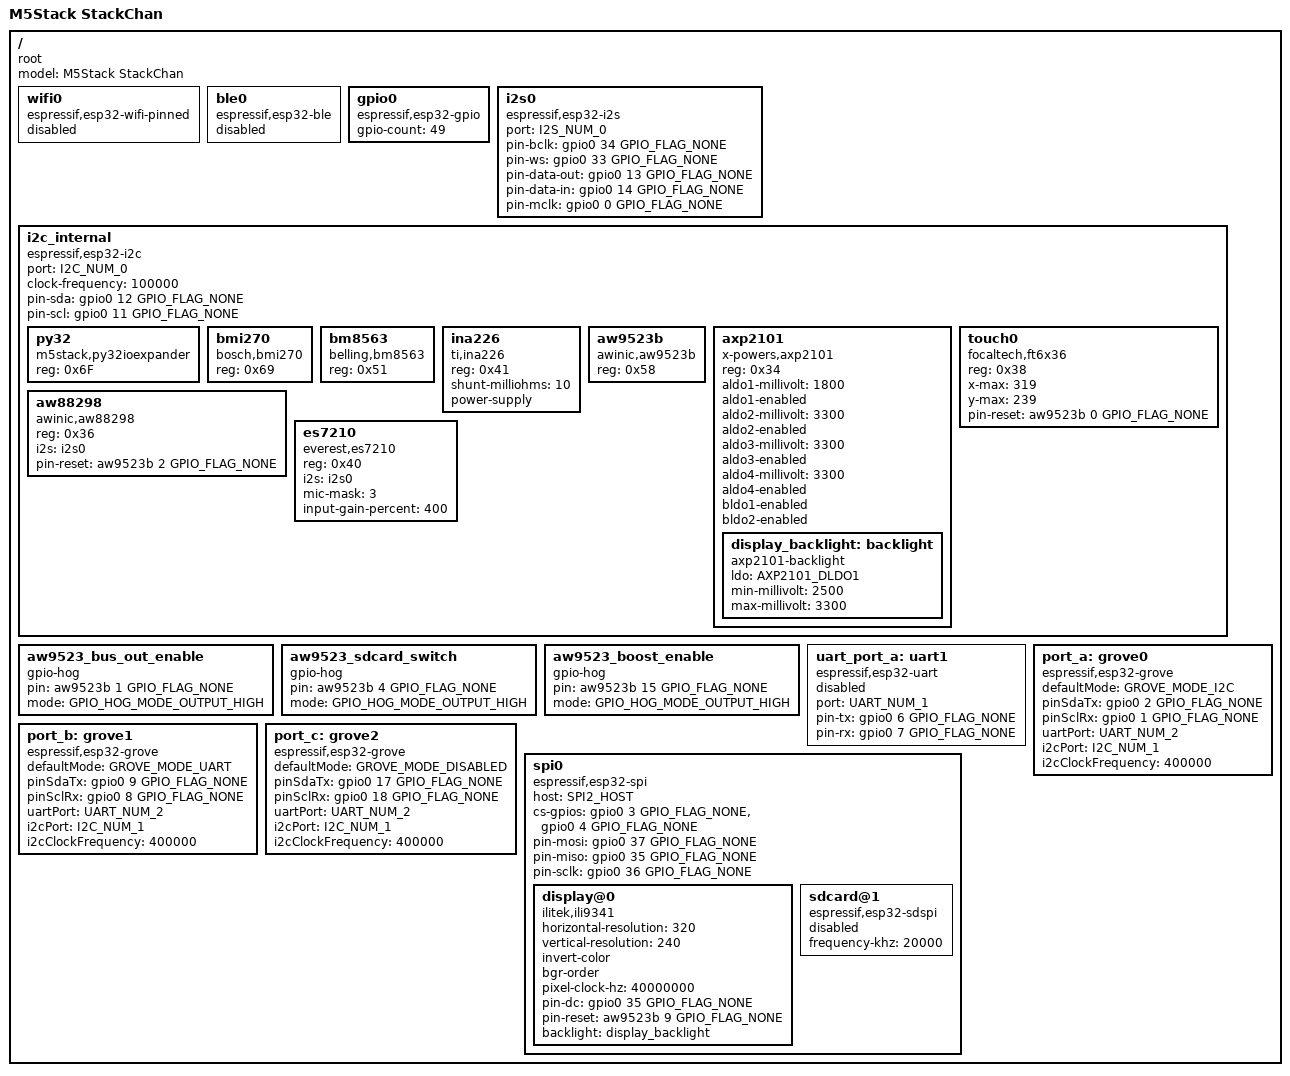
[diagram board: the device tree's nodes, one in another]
/dts-v1/;

#include <tactility/bindings/root.h>
#include <tactility/bindings/esp32_ble.h>
#include <tactility/bindings/esp32_wifi_pinned.h>
#include <tactility/bindings/esp32_gpio.h>
#include <tactility/bindings/esp32_grove.h>
#include <tactility/bindings/esp32_i2c.h>
#include <tactility/bindings/esp32_i2s.h>
#include <tactility/bindings/esp32_spi.h>
#include <tactility/bindings/esp32_uart.h>
#include <bindings/bmi270.h>
#include <bindings/bm8563.h>
#include <bindings/ina226.h>
#include <bindings/py32ioexpander.h>
#include <bindings/aw9523b.h>
#include <bindings/axp2101.h>
#include <bindings/axp2101_backlight.h>
#include <bindings/ft6x36.h>
#include <bindings/aw88298.h>
#include <bindings/es7210.h>
#include <bindings/ili9341.h>
#include <tactility/bindings/esp32_sdspi.h>
#include <tactility/bindings/gpio_hog.h>

// Reference: https://docs.m5stack.com/en/StackChan
/ {
	compatible = "root";
	model = "M5Stack StackChan";

	wifi0 {
		compatible = "espressif,esp32-wifi-pinned";
		status = "disabled";
	};

	ble0 {
		compatible = "espressif,esp32-ble";
		status = "disabled";
	};

	gpio0 {
		compatible = "espressif,esp32-gpio";
		gpio-count = <49>;
	};

	// AW88298 speaker + ES7210 microphone
	i2s0: i2s0 {
		compatible = "espressif,esp32-i2s";
		port = <I2S_NUM_0>;
		pin-bclk     = <&gpio0 34 GPIO_FLAG_NONE>;
		pin-ws       = <&gpio0 33 GPIO_FLAG_NONE>;
		pin-data-out = <&gpio0 13 GPIO_FLAG_NONE>;
		pin-data-in  = <&gpio0 14 GPIO_FLAG_NONE>;
		pin-mclk     = <&gpio0 0  GPIO_FLAG_NONE>;
	};

	i2c_internal {
		compatible = "espressif,esp32-i2c";
		port = <I2C_NUM_0>;
		clock-frequency = <100000>;
		pin-sda = <&gpio0 12 GPIO_FLAG_NONE>;
		pin-scl = <&gpio0 11 GPIO_FLAG_NONE>;

		// PY32L020 body IO expander — controls WS2812C LED ring (12 LEDs)
		py32 {
			compatible = "m5stack,py32ioexpander";
			reg = <0x6F>;
		};

		bmi270 {
			compatible = "bosch,bmi270";
			reg = <0x69>;
		};

		bm8563 {
			compatible = "belling,bm8563";
			reg = <0x51>;
		};

		ina226 {
			compatible = "ti,ina226";
			reg = <0x41>;
			shunt-milliohms = <10>;
			power-supply;
		};

		// AW9523B pin map (same wiring as CoreS3):
		// P0_0 = touch reset, P0_1 = bus-out enable, P0_2 = AW88298 reset,
		// P0_4 = SD card switch, P1_1 = LCD reset, P1_7 = boost enable (SY7088)
		aw9523b: aw9523b {
			compatible = "awinic,aw9523b";
			reg = <0x58>;
		};

		// Same rail assignment as CoreS3: ALDO1=AW88298, ALDO2=ES7210, ALDO3=camera
		// (not yet implemented, but harmless to power), ALDO4=TF/SD card. BLDO1/BLDO2 are
		// enabled with no specific voltage requirement - see the module's device_listener.
		axp2101 {
			compatible = "x-powers,axp2101";
			reg = <0x34>;
			aldo1-millivolt = <1800>;
			aldo1-enabled;
			aldo2-millivolt = <3300>;
			aldo2-enabled;
			aldo3-millivolt = <3300>;
			aldo3-enabled;
			aldo4-millivolt = <3300>;
			aldo4-enabled;
			bldo1-enabled;
			bldo2-enabled;

			// LCD backlight (DLDO1). Raw register codes [20,28] from the deprecated driver
			// map to [2500,3300]mV.
			display_backlight: backlight {
				compatible = "axp2101-backlight";
				ldo = <AXP2101_DLDO1>;
				min-millivolt = <2500>;
				max-millivolt = <3300>;
			};
		};

		touch0 {
			compatible = "focaltech,ft6x36";
			reg = <0x38>;
			x-max = <319>;
			y-max = <239>;
			pin-reset = <&aw9523b 0 GPIO_FLAG_NONE>;
		};

		aw88298 {
			compatible = "awinic,aw88298";
			reg = <0x36>;
			i2s = <&i2s0>;
			pin-reset = <&aw9523b 2 GPIO_FLAG_NONE>;
		};

		es7210 {
			compatible = "everest,es7210";
			reg = <0x40>;
			i2s = <&i2s0>;
			// Only MIC1/MIC2 are wired to real capsules (see schematic); MIC3/MIC4
			// slots carry AEC_P/AEC_N reference signal, not microphone audio.
			mic-mask = <3>;
			// M5Unified applies a 4x post-gain "magnification" for this exact mic
			// wiring (see M5Unified.cpp _mic_data_cb_cores3): the ES7210's own
			// hardware ADC gain (already near-max via the default 90% input volume
			// setting, ~34dB of its 0-37.5dB range) still isn't enough for these
			// capsules on their own.
			input-gain-percent = <400>;
		};

		// TODO: Si12T 3-zone head touch @ 0x68 — INT active-low, 10kΩ pull-up to 3.3V; driver not yet implemented
		// TODO: GC0308 camera @ 0x21 — requires i2c_master driver, not yet available
		// TODO: LTR-553ALS-WA proximity/light @ 0x23 — no driver yet
		// TODO: BMM150 magnetometer @ 0x10 — accessible only via BMI270 aux I2C
	};

	// Bus-out enable and SD card power switch are AW9523B pins with no owning peripheral
	// driver. Touch reset, AW88298 reset and LCD reset are handled directly by their own
	// device's pin-reset property instead (see touch0/aw88298/display@0 above/below).
	aw9523_bus_out_enable {
		compatible = "gpio-hog";
		pin = <&aw9523b 1 GPIO_FLAG_NONE>;
		mode = <GPIO_HOG_MODE_OUTPUT_HIGH>;
	};

	aw9523_sdcard_switch {
		compatible = "gpio-hog";
		pin = <&aw9523b 4 GPIO_FLAG_NONE>;
		mode = <GPIO_HOG_MODE_OUTPUT_HIGH>;
	};

	aw9523_boost_enable {
		compatible = "gpio-hog";
		pin = <&aw9523b 15 GPIO_FLAG_NONE>;
		mode = <GPIO_HOG_MODE_OUTPUT_HIGH>;
	};

	// TODO: Servo UART (SCS9009, 1 Mbaud) — TX=GPIO6, RX=GPIO7
	uart_port_a: uart1 {
		compatible = "espressif,esp32-uart";
		status = "disabled";
		port = <UART_NUM_1>;
		pin-tx = <&gpio0 6 GPIO_FLAG_NONE>;
		pin-rx = <&gpio0 7 GPIO_FLAG_NONE>;
	};

	port_a: grove0 {
		compatible = "espressif,esp32-grove";
		defaultMode = <GROVE_MODE_I2C>;
		pinSdaTx = <&gpio0 2 GPIO_FLAG_NONE>;
		pinSclRx = <&gpio0 1 GPIO_FLAG_NONE>;
		uartPort = <UART_NUM_2>;
		i2cPort = <I2C_NUM_1>;
		i2cClockFrequency = <400000>;
	};

	port_b: grove1 {
		compatible = "espressif,esp32-grove";
		defaultMode = <GROVE_MODE_UART>;
		pinSdaTx = <&gpio0 9 GPIO_FLAG_NONE>;
		pinSclRx = <&gpio0 8 GPIO_FLAG_NONE>;
		uartPort = <UART_NUM_2>;
		i2cPort = <I2C_NUM_1>;
		i2cClockFrequency = <400000>;
	};

	port_c: grove2 {
		compatible = "espressif,esp32-grove";
		defaultMode = <GROVE_MODE_DISABLED>;
		pinSdaTx = <&gpio0 17 GPIO_FLAG_NONE>;
		pinSclRx = <&gpio0 18 GPIO_FLAG_NONE>;
		uartPort = <UART_NUM_2>;
		i2cPort = <I2C_NUM_1>;
		i2cClockFrequency = <400000>;
	};

	spi0 {
		compatible = "espressif,esp32-spi";
		host = <SPI2_HOST>;
		cs-gpios = <&gpio0 3 GPIO_FLAG_NONE>, // Display
		           <&gpio0 4 GPIO_FLAG_NONE>; // SD card
		pin-mosi = <&gpio0 37 GPIO_FLAG_NONE>;
		pin-miso = <&gpio0 35 GPIO_FLAG_NONE>;
		pin-sclk = <&gpio0 36 GPIO_FLAG_NONE>;

		display@0 {
			compatible = "ilitek,ili9341";
			horizontal-resolution = <320>;
			vertical-resolution = <240>;
			invert-color;
			bgr-order;
			pixel-clock-hz = <40000000>;
			pin-dc = <&gpio0 35 GPIO_FLAG_NONE>;
			pin-reset = <&aw9523b 9 GPIO_FLAG_NONE>;
			backlight = <&display_backlight>;
		};

		sdcard@1 {
			compatible = "espressif,esp32-sdspi";
			status = "disabled"; // Must be started after display
			frequency-khz = <20000>;
		};
	};
};
